# SF32LB58x register map
File version: 1.0
CPU: CM33 r0p1, little endian, MPU, FPU, 3 interrupt priority bits
Registers are 32-bit, read-write, reset 0x0 unless marked. A register's access mark holds for its fields unless they carry their own. Offsets are from the block's base; [hi:lo] are bit positions; {n}, {i} and the like mark numbered series.

## LPSYS_CFG
Base 0x5000F000
0x00 SWCR — SW Control Register
  [1:0] SWSEL — 0 - SWD connected to HCPU 1 - SWD connected to LCPU 2 - SWD connected to ACPU
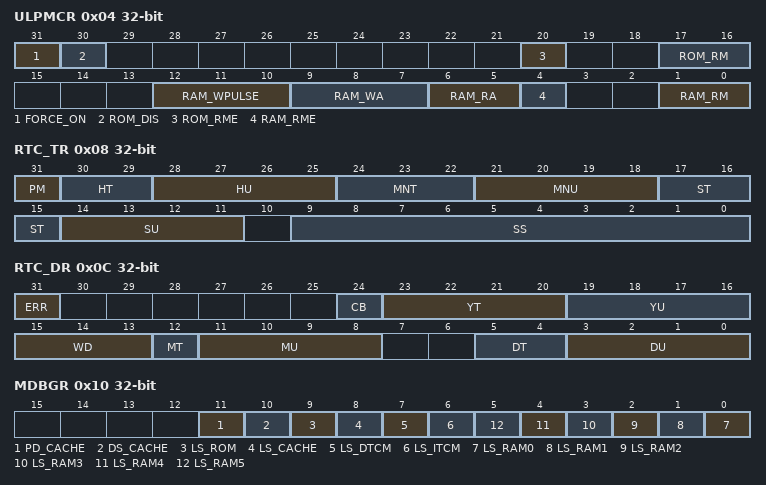
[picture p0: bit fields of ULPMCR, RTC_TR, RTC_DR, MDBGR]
0x04 ULPMCR — ULP Memory Control register
  [31] FORCE_ON — reserved for debug
  [30] ROM_DIS — reserved for debug
  [20] ROM_RME — reserved for debug
  [17:16] ROM_RM — reserved for debug
  [12:10] RAM_WPULSE — reserved for debug
  [9:7] RAM_WA — reserved for debug
  [6:5] RAM_RA — reserved for debug
  [4] RAM_RME — reserved for debug
  [1:0] RAM_RM — reserved for debug
0x08 RTC_TR — Mirrored RTC Time Register
  [31] PM — AM/PM notation 0: AM 1: PM
  [30:29] HT — Hour tens in BCD format
  [28:25] HU — Hour units in BCD format
  [24:22] MNT — Minute tens in BCD format
  [21:18] MNU — Minute units in BCD format
  [17:15] ST — Second tens in BCD format
  [14:11] SU — Second units in BCD format
  [9:0] SS — Sub-second counter
0x0C RTC_DR — Mirrored RTC Date Register
  [31] ERR — reserved for debug
  [24] CB — Century flag
  [23:20] YT — Year tens in BCD format
  [19:16] YU — Year units in BCD format
  [15:13] WD — Week day units 000: forbidden 001: Monday ... 111: Sunday
  [12] MT — Month tens in BCD format
  [11:8] MU — Month units in BCD format
  [5:4] DT — Date tens in BCD format
  [3:0] DU — Date units in BCD format
0x10 MDBGR — Memory Debug Register
  [11] PD_CACHE — reserved for debug
  [10] DS_CACHE — reserved for debug
  [9] LS_ROM — reserved for debug
  [8] LS_CACHE — reserved for debug
  [7] LS_DTCM — reserved for debug
  [6] LS_ITCM — reserved for debug
  [n] LS_RAM{n} (n=0..5) — reserved for debug
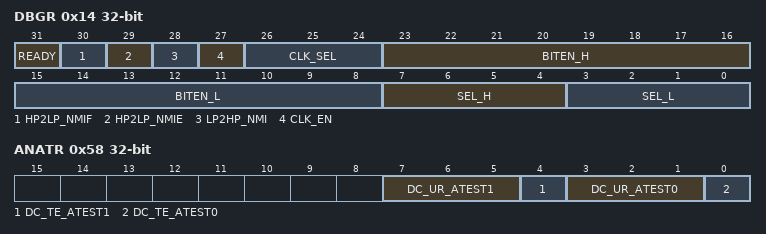
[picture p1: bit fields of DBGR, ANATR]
0x14 DBGR — Debug Register
  [31] READY — reserved for debug
  [30] HP2LP_NMIF — HP2LP NMI interrupt flag
  [29] HP2LP_NMIE — HP2LP NMI interrupt enable
  [28] LP2HP_NMI — set 1 to send NMI interrupt to HCPU
  [27] CLK_EN — reserved for debug
  [26:24] CLK_SEL — reserved for debug
  [23:16] BITEN_H — reserved for debug
  [15:8] BITEN_L — reserved for debug
  [7:4] SEL_H — reserved for debug
  [3:0] SEL_L — reserved for debug
0x54 SYSCR — System Configure Register
  [0] WDT2_REBOOT — If set to 1, WDT2 reset will reboot the whole chip
0x58 ANATR — Analog Test Register
  [7:5] DC_UR_ATEST1 — reserved for debug
  [4] DC_TE_ATEST1 — reserved for debug
  [3:1] DC_UR_ATEST0 — reserved for debug
  [0] DC_TE_ATEST0 — reserved for debug

## GPADC
Base 0x50016000
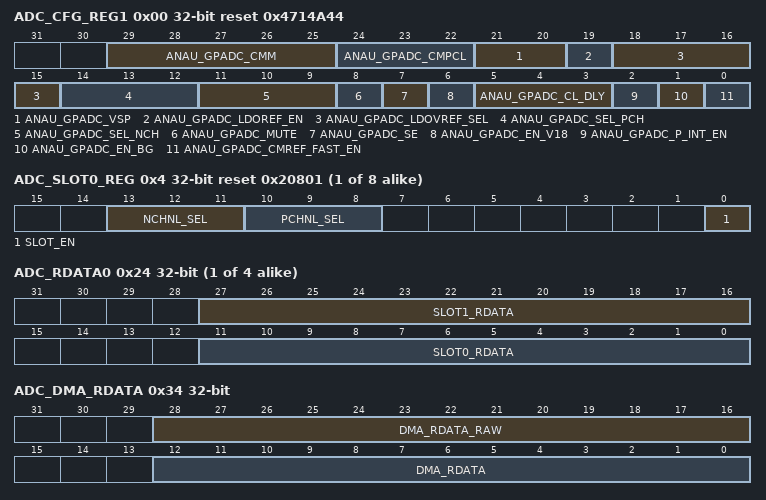
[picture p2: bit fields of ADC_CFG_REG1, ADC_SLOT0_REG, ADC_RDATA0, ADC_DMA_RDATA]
0x00 ADC_CFG_REG1 reset 0x4714A44 — ADC Analog Config Register 1
  [29:25] ANAU_GPADC_CMM — Tune CDAC CM voltage 375mV range (increasing) / 25mV step, 8: for 0.5V Vcm,in
  [24:22] ANAU_GPADC_CMPCL — Tune ADC comparator CL= 3: 40f, range: 10fF (0) ~ 80fF (7) / 10fF step
  [21:20] ANAU_GPADC_VSP — Set comparator input CM in sampling phase, 0.539V (0) / 0.578V (1) / 0.642V (2) / 0.784V (3)
  [19] ANAU_GPADC_LDOREF_EN — Enable LDORF for ADC VREF
  [18:15] ANAU_GPADC_LDOVREF_SEL — Set reference voltage for LDOREF, range = 0.35V(0) ~ 0.65V(15), step = 20mV
  [14:12] ANAU_GPADC_SEL_PCH — Select P-side input channel for GPADC, 0 for channel 0, 7 for channel 7, effective when force on
  [11:9] ANAU_GPADC_SEL_NCH — Select N-side input channel for GPADC, 0 for channel 0, 7 for channel 7, effective when force on
  [8] ANAU_GPADC_MUTE — Short GPADC P and N input to CMREF, i.e., VREF/2
  [7] ANAU_GPADC_SE — Set GPADC in single-ended mode, signal range at P-input: 0 ~ VREF
  [6] ANAU_GPADC_EN_V18
  [5:3] ANAU_GPADC_CL_DLY
  [2] ANAU_GPADC_P_INT_EN
  [1] ANAU_GPADC_EN_BG
  [0] ANAU_GPADC_CMREF_FAST_EN
{0x4+4i} ADC_SLOT{i}_REG reset 0x20801 (i=0..7) — ADC Slot{i} Config Register
  [13:11] NCHNL_SEL, [10:8] PCHNL_SEL, [0] SLOT_EN
{0x24+4i} ADC_RDATA{i} (i=0..3) — ADC Read Data{i}
  [27:16] SLOT{2i+1}_RDATA, [11:0] SLOT{2i}_RDATA
0x34 ADC_DMA_RDATA — ADC Read Data For DMA
  [28:16] DMA_RDATA_RAW, [12:0] DMA_RDATA
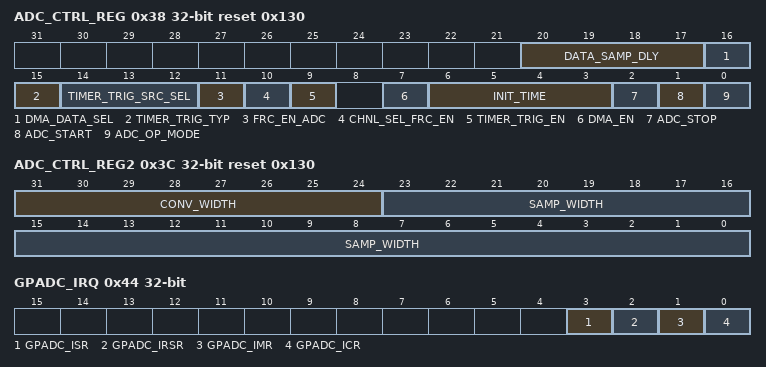
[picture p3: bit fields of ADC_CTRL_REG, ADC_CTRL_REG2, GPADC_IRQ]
0x38 ADC_CTRL_REG reset 0x130 — ADC Control Register
  [20:17] DATA_SAMP_DLY
  [16] DMA_DATA_SEL — 0: combined data 1: raw data
  [15] TIMER_TRIG_TYP — 0: pulse no edge detect needed 1: level,need edge detect
  [14:12] TIMER_TRIG_SRC_SEL
  [11] FRC_EN_ADC
  [10] CHNL_SEL_FRC_EN
  [9] TIMER_TRIG_EN
  [7] DMA_EN
  [6:3] INIT_TIME
  [2] ADC_STOP
  [1] ADC_START
  [0] ADC_OP_MODE — 0: finite 1: inifinite
0x3C ADC_CTRL_REG2 reset 0x130 — ADC Control Register2
  [31:24] CONV_WIDTH, [23:0] SAMP_WIDTH
0x44 GPADC_IRQ
  [3] GPADC_ISR, [2] GPADC_IRSR, [1] GPADC_IMR, [0] GPADC_ICR

## TSEN
Base 0x5001A000
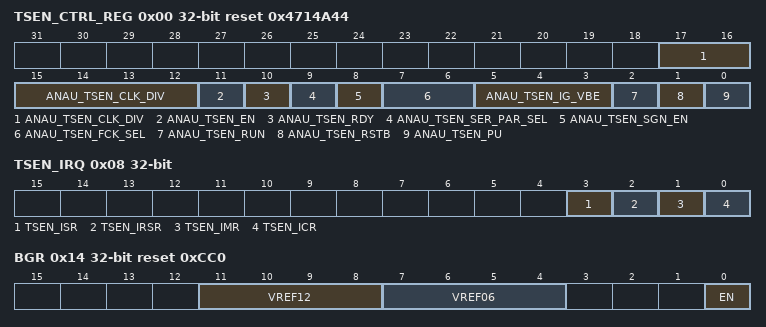
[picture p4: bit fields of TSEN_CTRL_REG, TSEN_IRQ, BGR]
0x00 TSEN_CTRL_REG reset 0x4714A44 — TSEN Analog Control Register
  [17:12] ANAU_TSEN_CLK_DIV — gen tsen clk by divide hclk by anau_tsen_clk_div
  [11] ANAU_TSEN_EN — Enable tsen digital module
  [10] ANAU_TSEN_RDY — tsen ready
  [9] ANAU_TSEN_SER_PAR_SEL — serial-parallel output selection
  [8] ANAU_TSEN_SGN_EN — signature-mode enable
  [7:6] ANAU_TSEN_FCK_SEL — select internal clock frequency
  [5:3] ANAU_TSEN_IG_VBE — bias current selection to tune vba
  [2] ANAU_TSEN_RUN — enable tsen run
  [1] ANAU_TSEN_RSTB — resetb for tsen
  [0] ANAU_TSEN_PU — power up tsen
0x04 TSEN_RDATA — Tsen Read Data
  [11:0] TSEN_RDATA
0x08 TSEN_IRQ
  [3] TSEN_ISR, [2] TSEN_IRSR, [1] TSEN_IMR, [0] TSEN_ICR
0x10 ANAU_ANA_TP — Tsen IRQ Register
  [0] ANAU_IARY_EN
0x14 BGR reset 0xCC0 — Bandgap registers
  [11:8] VREF12 — select VREF 1.2V
  [7:4] VREF06 — select VREF 0.6V
  [0] EN — Bandgap enable
